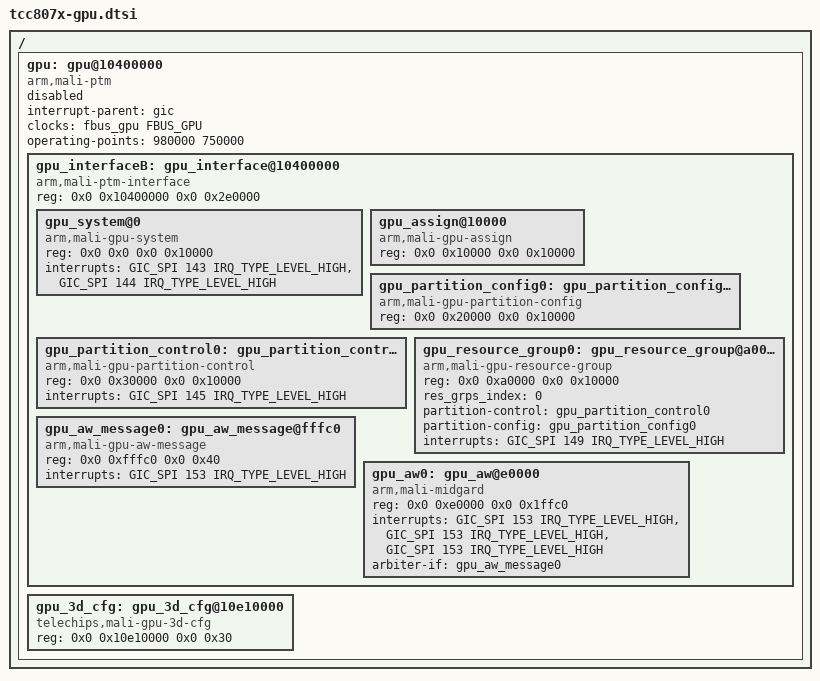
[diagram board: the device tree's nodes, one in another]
// SPDX-License-Identifier: (GPL-2.0-or-later OR MIT)
/*
 * Copyright (C) 2023 Telechips Inc.
 */

/ {
	gpu: gpu@10400000 {
		interrupt-parent = <&gic>;
		compatible = "arm,mali-ptm";
		ranges;
		#address-cells = <2>;
		#size-cells = <2>;
		status = "disabled";
		/* power */
		clocks = <&fbus_gpu FBUS_GPU>;
		clock-names = "mali_clk";
		operating-points = <
			/* KHz uV */
			980000 750000
		>;

		/* bus AXI-B */
		gpu_interfaceB: gpu_interface@10400000 {
			compatible = "arm,mali-ptm-interface";
			ranges = <0x0 0x0 0x0 0x10400000 0x0 0x2e0000>;
			reg = <0x0 0x10400000 0x0 0x2e0000>;
			#address-cells = <2>;
			#size-cells = <2>;

			gpu_system@0 {
				compatible = "arm,mali-gpu-system";
				reg = <0x0 0x0 0x0 0x10000>;
				interrupts = <GIC_SPI 143 IRQ_TYPE_LEVEL_HIGH>,
					     <GIC_SPI 144 IRQ_TYPE_LEVEL_HIGH>;
				interrupt-names = "PTM_UNCORRECTED_ERROR_IRQ",
						  "PTM_DEFERRED_ERROR_IRQ";
			};

			gpu_assign@10000 {
				compatible = "arm,mali-gpu-assign";
				reg = <0x0 0x10000 0x0 0x10000>;
			};

			/* R0 */
			gpu_partition_config0: gpu_partition_config@20000 {
				compatible = "arm,mali-gpu-partition-config";
				reg = <0x0 0x20000 0x0 0x10000>;
			};

			gpu_partition_control0: gpu_partition_control@30000 {
				compatible = "arm,mali-gpu-partition-control";
				reg = <0x0 0x30000 0x0 0x10000>;
				interrupts = <GIC_SPI 145 IRQ_TYPE_LEVEL_HIGH>;
				interrupt-names = "PTM_PARTITION_IRQ";
			};

			gpu_resource_group0: gpu_resource_group@a0000 {
				compatible = "arm,mali-gpu-resource-group";
				reg = <0x0 0xa0000 0x0 0x10000>;
				res_grps_index = <0>;
				partition-control = <&gpu_partition_control0>;
			partition-config = <&gpu_partition_config0>;
			interrupts = <GIC_SPI 149 IRQ_TYPE_LEVEL_HIGH>;
			interrupt-names = "PTM_GROUP_IRQ";
			};

			gpu_aw_message0: gpu_aw_message@fffc0 {
				compatible = "arm,mali-gpu-aw-message";
				reg = <0x0 0xfffc0 0x0 0x40>;
				interrupts = <GIC_SPI 153 IRQ_TYPE_LEVEL_HIGH>;
				interrupt-names = "PTM_MESSAGE";
			};

			gpu_aw0: gpu_aw@e0000 {
				compatible = "arm,mali-midgard";
				reg = <0x0 0xe0000 0x0 0x1ffc0>;
				interrupts = <GIC_SPI 153 IRQ_TYPE_LEVEL_HIGH>,
					     <GIC_SPI 153 IRQ_TYPE_LEVEL_HIGH>,
					     <GIC_SPI 153 IRQ_TYPE_LEVEL_HIGH>;
				interrupt-names = "JOB", "MMU", "GPU";
				arbiter-if = <&gpu_aw_message0>;
			};
		};

		gpu_3d_cfg: gpu_3d_cfg@10e10000 {
	                compatible = "telechips,mali-gpu-3d-cfg";
	                reg = <0x0 0x10e10000 0x0 0x30>;        /* 3D BUS Configuration and Control */
		};
	};
};
